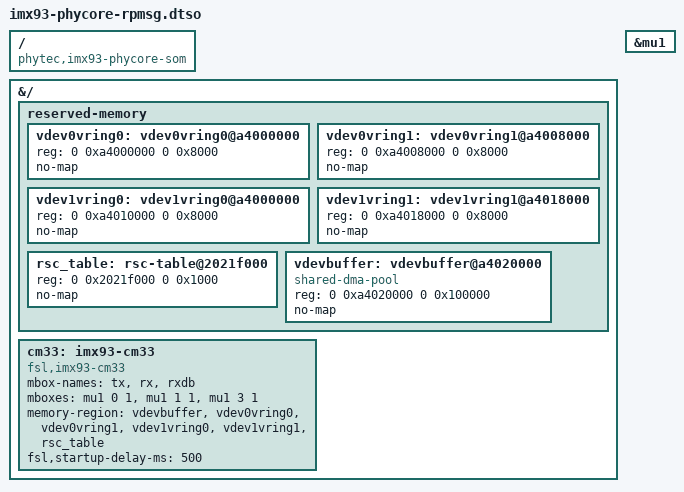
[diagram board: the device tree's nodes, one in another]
// SPDX-License-Identifier: GPL-2.0
/*
 * Copyright (C) 2023 PHYTEC Messtechnik GmbH
 * Author: Primoz Fiser <primoz.fiser@norik.com>
 */

/dts-v1/;
/plugin/;

/ {
	compatible = "phytec,imx93-phycore-som";
};

&{/} {
	reserved-memory {
		#address-cells = <2>;
		#size-cells = <2>;

		vdev0vring0: vdev0vring0@a4000000 {
			reg = <0 0xa4000000 0 0x8000>;
			no-map;
		};

		vdev0vring1: vdev0vring1@a4008000 {
			reg = <0 0xa4008000 0 0x8000>;
			no-map;
		};

		vdev1vring0: vdev1vring0@a4000000 {
			reg = <0 0xa4010000 0 0x8000>;
			no-map;
		};

		vdev1vring1: vdev1vring1@a4018000 {
			reg = <0 0xa4018000 0 0x8000>;
			no-map;
		};

		rsc_table: rsc-table@2021f000 {
			reg = <0 0x2021f000 0 0x1000>;
			no-map;
		};

		vdevbuffer: vdevbuffer@a4020000 {
			compatible = "shared-dma-pool";
			reg = <0 0xa4020000 0 0x100000>;
			no-map;
		};
	};

	cm33: imx93-cm33 {
		compatible = "fsl,imx93-cm33";
		mbox-names = "tx", "rx", "rxdb";
		mboxes = <&mu1 0 1
			  &mu1 1 1
			  &mu1 3 1>;
		memory-region = <&vdevbuffer>, <&vdev0vring0>, <&vdev0vring1>,
				<&vdev1vring0>, <&vdev1vring1>, <&rsc_table>;
		fsl,startup-delay-ms = <500>;
	};
};

&mu1 {
	status = "okay";
};
